# R9A02G021 register map
Vendor: Renesas Electronics Corporation; Series: RISC-V; File version: 1.10.00 + 202304131714_CPU
CPU: other r0p0, little endian, no MPU, no FPU, VTOR, 4 interrupt priority bits, 32 interrupts
Registers are 8-bit, read-write, reset 0x0 unless marked. A register's access mark holds for its fields unless they carry their own. Offsets are from the block's base; [hi:lo] are bit positions; {n}, {i} and the like mark numbered series; 'fields as' and 'values as' point back to an identical list; <NAME> marks a mode.

## SYSC — System Control
Base 0x4001E000
0x0C SBYCR 16-bit — Standby Control Register
  [15] SSBY — Software Standby Mode Select
    0=Sleep mode; 1=Software Standby mode
0x1C MSTPCRA 32-bit reset 0xFFBFFFFF — Module Stop Control Register A
  [22] MSTPA22 — DTC Module Stop
    0=Cancel the module-stop state; 1=Enter the module-stop state
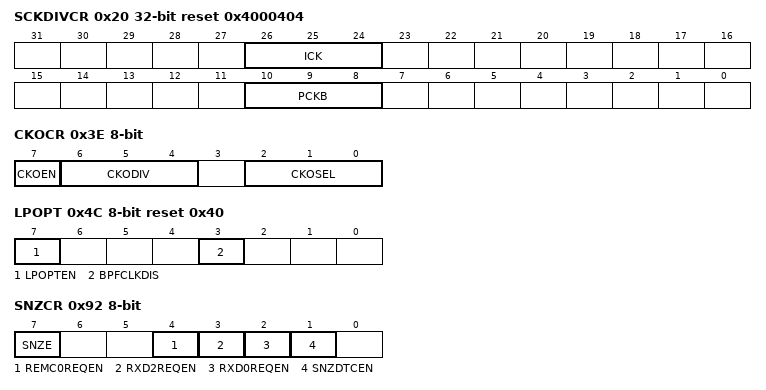
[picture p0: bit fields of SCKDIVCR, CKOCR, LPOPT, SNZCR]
0x20 SCKDIVCR 32-bit reset 0x4000404 — System Clock Division Control Register
  [26:24] ICK — System Clock (ICLK) Select
    0=x 1/1; 1=x 1/2; 2=x 1/4; 3=x 1/8; 4=x 1/16; 5=x 1/32; 6=x 1/64; other=Others (Settings prohibited)
  [10:8] PCKB — Peripheral Module Clock B (PCLKB) Select
    values as ICK
0x26 SCKSCR reset 0x1 — System Clock Source Control Register
  [2:0] CKSEL — Clock Source Select
    0=HOCO; 1=MOCO; 2=LOCO; 3=External clock input (EXTAL); 4=Sub-clock oscillator (SOSC); 5=Setting prohibited; 6=Setting prohibited; 7=Setting prohibited
0x31 MEMWAIT — Memory Wait Cycle Control Register for Code Flash
  [0] MEMWAIT — Memory Wait Cycle Select for Code Flash
    0=No wait; 1=Wait
0x32 MOSCCR reset 0x1 — External Clock Input Control Register
  [0] MOSTP — External Clock Input Stop
    0=Operate the external clock input; 1=Stop the external clock input
0x36 HOCOCR (reset mask 0xFE) — High-Speed On-Chip Oscillator Control Register
  [0] HCSTP — HOCO Stop
    0=Operate the HOCO clock ,; 1=Stop the HOCO clock
0x37 HOCOCR2 (reset mask 0xC7) — High-Speed On-Chip Oscillator Control Register 2
  [5:3] HCFRQ1 — HOCO Frequency Setting 1
    0=24 MHz; 2=32 MHz; 4=48 MHz; other=Others (Setting prohibited)
0x38 MOCOCR — Middle-Speed On-Chip Oscillator Control Register
  [0] MCSTP — MOCO Stop
    0=MOCO clock is operating; 1=MOCO clock is stopped
0x3C OSCSF ro (reset mask 0xFE) — Oscillation Stabilization Flag Register
  [0] HOCOSF — HOCO Clock Oscillation Stabilization Flag
    0=The HOCO clock is stopped or is not yet stable; 1=The HOCO clock is stable, so is available for use as the system clock
0x3E CKOCR — Clock Out Control Register
  [7] CKOEN — Clock Out Enable
    0=Disable clock out; 1=Enable clock out
  [6:4] CKODIV — Clock Output Frequency Division Ratio
    0=x 1/1; 1=x 1/2; 2=x 1/4; 3=x 1/8; 4=x 1/16; 5=x 1/32; 6=x 1/64; 7=x 1/128
  [2:0] CKOSEL — Clock Out Source Select
    0=HOCO (value after reset); 1=MOCO; 2=LOCO; 3=External clock input (EXTAL); 4=Sub-clock oscillator (SOSC); 5=Setting prohibited; other=Others (Setting prohibited)
0x4C LPOPT reset 0x40 — Lower Power Operation Control Register
  [7] LPOPTEN — Lower Power Operation Enable
    0=All lower power counter measure disable; 1=All lower power counter measure enable
  [3] BPFCLKDIS — BPF Clock Disable Control
    0=Flash register R/W clock operates as normal; 1=Flash register R/W clock stops
0x54 OSMCR — Subsystem Clock Supply Mode Control Register
  [0] WUTMMCK0 — Selection of the operating clock for the realtime clock, 32-bit interval timer, serial interfaces UARTA0 and UARTA1, remote control signal receiver
    0=Subsystem clock (SOSC); 1=Low-speed on-chip oscillator clock (LOCO)
0x61 MOCOUTCR — MOCO User Trimming Control Register
  [7:0] MOCOUTRM — MOCO User Trimming
0x62 HOCOUTCR — HOCO User Trimming Control Register
  [7:0] HOCOUTRM — HOCO User Trimming
0x92 SNZCR — Snooze Control Register
  [7] SNZE — Snooze mode Enable
    0=Disable Snooze mode; 1=Enable Snooze mode
  [4] REMC0REQEN — RIN0 Snooze Request Enable
    0=Ignore RIN0 edge in Software Standby mode; 1=Detect RIN0 edge in Software Standby mode
  [3] RXD2REQEN — RXD2 or SCK20 Snooze Request Enable
    0=Ignore RXD2 or SCK20 edge in Software Standby mode; 1=Detect RXD2 or SCK20 edge in Software Standby mode
  [2] RXD0REQEN — RXD0 or SCK00 Snooze Request Enable
    0=Ignore RXD0 or SCK00 edge in Software Standby mode; 1=Detect RXD0 or SCK00 edge in Software Standby mode
  [1] SNZDTCEN — DTC Enable in Snooze mode
    0=Disable DTC operation; 1=Enable DTC operation
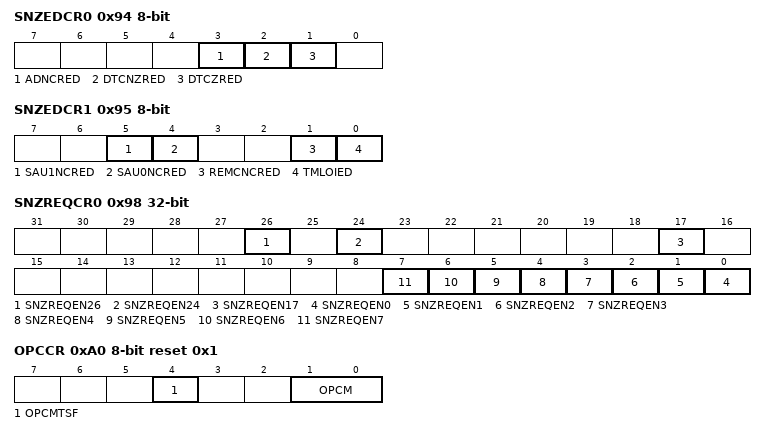
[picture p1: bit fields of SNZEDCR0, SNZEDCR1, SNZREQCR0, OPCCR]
0x94 SNZEDCR0 — Snooze End Control Register 0
  [all] fields
    0=Disable the snooze end request; 1=Enable the snooze end request
  [3] ADNCRED — ADC Compare Mismatch Snooze End Enable
  [2] DTCNZRED — Not Last DTC Transmission Completion Snooze End Enable
  [1] DTCZRED — Last DTC Transmission Completion Snooze End Enable
0x95 SNZEDCR1 — Snooze End Control Register 1
  [all] fields
    values as the fields of SNZEDCR0
  [5] SAU1NCRED — SAU1 No-Interrupt Error Completion Snooze End Enable
  [4] SAU0NCRED — SAU0 No-Interrupt Error Completion Snooze End Enable
  [1] REMCNCRED — REMC No-Interrupt Completion Snooze End Enable
  [0] TMLOIED — TML32 Interrupt Snooze End Enable
0x98 SNZREQCR0 32-bit — Snooze Request Control Register 0
  [all] fields
    0=Disable the snooze request; 1=Enable the snooze request
  [26] SNZREQEN26 — Enable TML32 snooze request
  [24] SNZREQEN24 — Enable RTC alarm snooze request
  [17] SNZREQEN17 — Enable KEY_INTKR snooze request
  [n] SNZREQEN{n} (n=0..7) — Enable IRQ{n} pin snooze request
0x9F PSMCR — Power Save Memory Control Register
  [1:0] PSMC — Power Save Memory Control
    0=All SRAMs are on in Software Standby mode; 1=8 KB SRAM (0x2000_0000 to 0x2000_0FFF and 0x2000_4000 to 0x2000_4FFF) is on, in Software Standby mode; 2=Setting prohibited; 3=Setting prohibited
0xA0 OPCCR reset 0x1 — Operating Power Control Register
  [4] OPCMTSF ro — Operating Power Control Mode Transition Status Flag
    0=Transition completed; 1=During transition
  [1:0] OPCM — Operating Power Control Mode Select
    0=High-speed mode; 1=Middle-speed mode; 2=Setting prohibited; 3=Low-speed mode
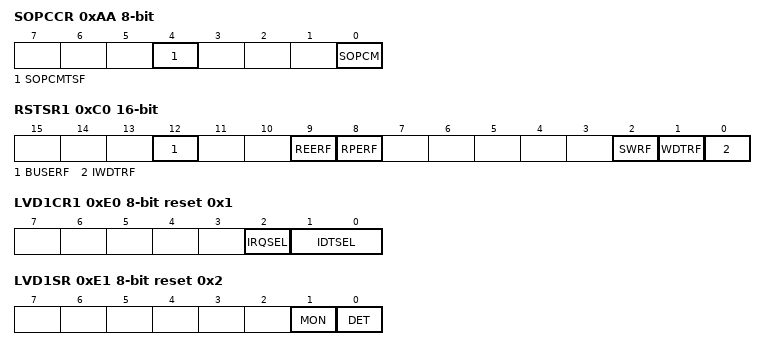
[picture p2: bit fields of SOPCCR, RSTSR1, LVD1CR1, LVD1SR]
0xAA SOPCCR — Sub Operating Power Control Register
  [4] SOPCMTSF ro — Operating Power Control Mode Transition Status Flag
    0=Transition completed; 1=During transition
  [0] SOPCM — Sub Operating Power Control Mode Select
    0=Other than Subosc-speed mode; 1=Subosc-speed mode
0xC0 RSTSR1 16-bit (reset mask 0xECF8) — Reset Status Register 1
  [12] BUSERF — Bus Error Reset Detect Flag
    0=Bus error reset not detected; 1=Bus error reset detected
  [9] REERF — SRAM ECC Error Reset Detect Flag
    0=SRAM ECC error reset not detected; 1=SRAM ECC error reset detected
  [8] RPERF — SRAM Parity Error Reset Detect Flag
    0=SRAM parity error reset not detected; 1=SRAM parity error reset detected
  [2] SWRF — Software Reset Detect Flag
    0=Software reset not detected; 1=Software reset detected
  [1] WDTRF — Watchdog Timer Reset Detect Flag
    0=Watchdog timer reset not detected; 1=Watchdog timer reset detected
  [0] IWDTRF — Independent Watchdog Timer Reset Detect Flag
    0=Independent watchdog timer reset not detected; 1=Independent watchdog timer reset detected
0xE0 LVD1CR1 reset 0x1 — Voltage Monitor 1 Circuit Control Register
  [2] IRQSEL — Voltage Monitor 1 Interrupt Type Select
    0=Non-maskable interrupt; 1=Maskable interrupt
  [1:0] IDTSEL — Voltage Monitor 1 Interrupt Generation Condition Select
    0=When VCC >= Vdet1 (rise) is detected; 1=When VCC < Vdet1 (fall) is detected; 2=When fall and rise are detected; 3=Settings prohibited
0xE1 LVD1SR reset 0x2 — Voltage Monitor 1 Circuit Status Register
  [1] MON ro — Voltage Monitor 1 Signal Monitor Flag
    0=VCC < Vdet1; 1=VCC >= Vdet1 or MON is disabled
  [0] DET — Voltage Monitor 1 Voltage Variation Detection Flag
    0=Not detected; 1=Vdet1 crossing is detected
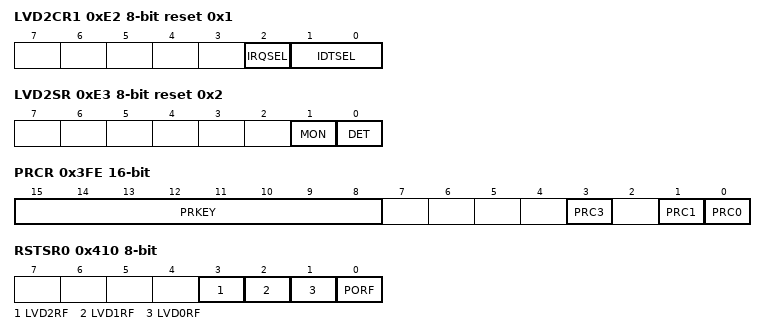
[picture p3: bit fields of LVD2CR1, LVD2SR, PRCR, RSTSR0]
0xE2 LVD2CR1 reset 0x1 — Voltage Monitor 2 Circuit Control Register 1
  [2] IRQSEL — Voltage Monitor 2 Interrupt Type Select
    0=Non-maskable interrupt; 1=Maskable interrupt
  [1:0] IDTSEL — Voltage Monitor 2 Interrupt Generation Condition Select
    0=When VCC >= Vdet2 (rise) is detected; 1=When VCC < Vdet2 (fall) is detected; 2=When fall and rise are detected; 3=Settings prohibited
0xE3 LVD2SR reset 0x2 — Voltage Monitor 2 Circuit Status Register
  [1] MON ro — Voltage Monitor 2 Signal Monitor Flag
    0=VCC < Vdet2; 1=VCC >= Vdet2 or MON is disabled
  [0] DET — Voltage Monitor 2 Voltage Variation Detection Flag
    0=Not detected; 1=Vdet2 crossing is detected
0x3FE PRCR 16-bit — Protect Register
  [15:8] PRKEY wo — PRC Key Code
  [3] PRC3 — Enable writing to the registers related to the LVD
    0=Disable writes; 1=Enable writes
  [1] PRC1 — Enable writing to the registers related to the low power modes
    0=Disable writes; 1=Enable writes
  [0] PRC0 — Enable writing to the registers related to the clock generation circuit
    0=Disable writes; 1=Enable writes
0x40E SYOCDCR — System Control OCD Control Register
  [7] DBGEN — Debugger Enable bit
    0=On-chip debugger is disabled; 1=On-chip debugger is enabled
0x410 RSTSR0 (reset mask 0xF0) — Reset Status Register 0
  [3] LVD2RF — Voltage Monitor 2 Reset Detect Flag
    0=Voltage monitor 2 reset not detected; 1=Voltage monitor 2 reset detected
  [2] LVD1RF — Voltage Monitor 1 Reset Detect Flag
    0=Voltage monitor 1 reset not detected; 1=Voltage monitor 1 reset detected
  [1] LVD0RF — Voltage Monitor 0 Reset Detect Flag
    0=Voltage monitor 0 reset not detected; 1=Voltage monitor 0 reset detected
  [0] PORF — Power-On Reset Detect Flag
    0=Power-on reset not detected; 1=Power-on reset detected
0x411 RSTSR2 (reset mask 0xFE) — Reset Status Register 2
  [0] CWSF — Cold/Warm Start Determination Flag
    0=Cold start; 1=Warm start
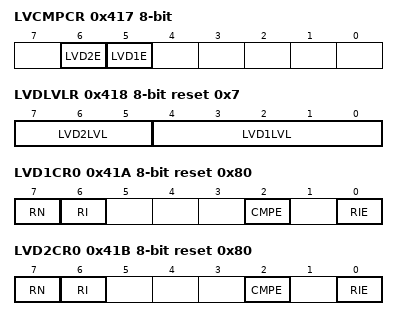
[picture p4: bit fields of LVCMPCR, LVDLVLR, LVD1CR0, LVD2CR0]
0x417 LVCMPCR — Voltage Monitor Circuit Control Register
  [6] LVD2E — Voltage Detection 2 Enable
    0=Voltage detection 2 circuit disabled; 1=Voltage detection 2 circuit enabled
  [5] LVD1E — Voltage Detection 1 Enable
    0=Voltage detection 1 circuit disabled; 1=Voltage detection 1 circuit enabled
0x418 LVDLVLR reset 0x7 — Voltage Detection Level Select Register
  [7:5] LVD2LVL — Voltage Detection 2 Level Select (Standard voltage during fall in voltage)
    {v}=Vdet2_{v} (v=0..3); other=Others (Setting prohibited)
  [4:0] LVD1LVL — Voltage Detection 1 Level Select (Standard voltage during fall in voltage)
    {v}=Vdet1_{v} (v=0..9); 10=Vdet1_A; 11=Vdet1_B; 12=Vdet1_C; 13=Vdet1_D; 14=Vdet1_E; 15=Vdet1_F; other=Others (Setting prohibited)
0x41A LVD1CR0 reset 0x80 — Voltage Monitor 1 Circuit Control Register 0
  [7] RN — Voltage Monitor 1 Reset Negate Select
    0=Negate after a stabilization time (tLVD1) from the time that VCC > Vdet1 is detected; 1=Negate after a stabilization time (tLVD1) from the time that LVD1 reset is asserted
  [6] RI — Voltage Monitor 1 Circuit Mode Select
    0=Generate voltage monitor 1 interrupt on Vdet1 crossing; 1=Enable voltage monitor 1 reset when the voltage falls to and below Vdet1
  [2] CMPE — Voltage Monitor 1 Circuit Comparison Result Output Enable
    0=Disable voltage monitor 1 circuit comparison result output; 1=Enable voltage monitor 1 circuit comparison result output
  [0] RIE — Voltage Monitor 1 Interrupt/Reset Enable
    0=Disable; 1=Enable
0x41B LVD2CR0 reset 0x80 — Voltage Monitor 2 Circuit Control Register 0
  [7] RN — Voltage Monitor 2 Reset Negate Select
    0=Negate after a stabilization time (tLVD2) from the time that VCC > Vdet2 is detected; 1=Negate after a stabilization time (tLVD2) from the time that LVD2 reset is asserted
  [6] RI — Voltage Monitor 2 Circuit Mode Select
    0=Generate voltage monitor 2 interrupt on Vdet2 crossing; 1=Enable voltage monitor 2 reset when the voltage falls to and below Vdet2
  [2] CMPE — Voltage Monitor 2 Circuit Comparison Result Output Enable
    0=Disable voltage monitor 2 circuit comparison result output; 1=Enable voltage monitor 2 circuit comparison result output
  [0] RIE — Voltage Monitor 2 Interrupt/Reset Enable
    0=Disable; 1=Enable
0x480 SOSCCR reset 0x1 — Sub-Clock Oscillator Control Register
  [0] SOSTP — Sub Clock Oscillator Stop
    0=Operate the sub-clock oscillator; 1=Stop the sub-clock oscillator
0x481 SOMCR — Sub-Clock Oscillator Mode Control Register
  [1:0] SODRV — Sub-Clock Oscillator Drive Capability Switching
    0=Normal Mode; 1=Low Power Mode 1; 2=Low Power Mode 2; 3=Low Power Mode 3
0x482 SOMRG — Sub-Clock Oscillator Margin Check Register
  [1:0] SOSCMRG — Sub Clock Oscillator Margin check Switching
    0=Normal Current; 1=Lower Margin check; 2=Upper Margin check; 3=Setting prohibited
0x490 LOCOCR — Low-Speed On-Chip Oscillator Control Register
  [0] LCSTP — LOCO Stop
    0=Operate the LOCO clock; 1=Stop the LOCO clock
0x492 LOCOUTCR — LOCO User Trimming Control Register
  [7:0] LOCOUTRM — LOCO User Trimming
